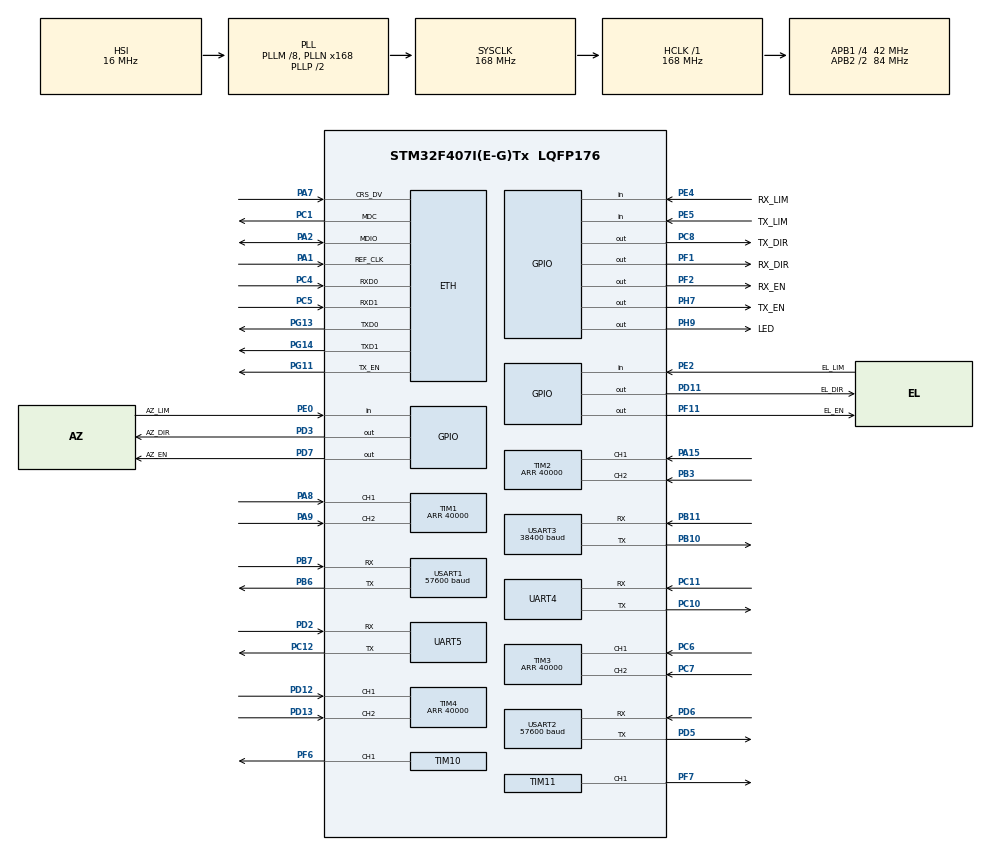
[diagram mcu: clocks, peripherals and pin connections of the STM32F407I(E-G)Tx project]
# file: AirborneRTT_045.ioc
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Dma.Request0=USART1_TX
Dma.Request1=USART2_TX
Dma.Request2=USART3_TX
Dma.Request3=UART4_TX
Dma.UART4_TX.3.Direction=DMA_MEMORY_TO_PERIPH
Dma.UART4_TX.3.FIFOMode=DMA_FIFOMODE_DISABLE
Dma.UART4_TX.3.Instance=DMA1_Stream4
Dma.UART4_TX.3.MemDataAlignment=DMA_MDATAALIGN_BYTE
Dma.UART4_TX.3.MemInc=DMA_MINC_ENABLE
Dma.UART4_TX.3.Mode=DMA_NORMAL
Dma.UART4_TX.3.PeriphDataAlignment=DMA_PDATAALIGN_BYTE
Dma.UART4_TX.3.PeriphInc=DMA_PINC_DISABLE
Dma.UART4_TX.3.Priority=DMA_PRIORITY_LOW
Dma.USART1_TX.0.Direction=DMA_MEMORY_TO_PERIPH
Dma.USART1_TX.0.FIFOMode=DMA_FIFOMODE_DISABLE
Dma.USART1_TX.0.Instance=DMA2_Stream7
Dma.USART1_TX.0.MemDataAlignment=DMA_MDATAALIGN_BYTE
Dma.USART1_TX.0.MemInc=DMA_MINC_ENABLE
Dma.USART1_TX.0.Mode=DMA_NORMAL
Dma.USART1_TX.0.PeriphDataAlignment=DMA_PDATAALIGN_BYTE
Dma.USART1_TX.0.PeriphInc=DMA_PINC_DISABLE
Dma.USART1_TX.0.Priority=DMA_PRIORITY_LOW
Dma.USART2_TX.1.Direction=DMA_MEMORY_TO_PERIPH
Dma.USART2_TX.1.FIFOMode=DMA_FIFOMODE_DISABLE
Dma.USART2_TX.1.Instance=DMA1_Stream6
Dma.USART2_TX.1.MemDataAlignment=DMA_MDATAALIGN_BYTE
Dma.USART2_TX.1.MemInc=DMA_MINC_ENABLE
Dma.USART2_TX.1.Mode=DMA_NORMAL
Dma.USART2_TX.1.PeriphDataAlignment=DMA_PDATAALIGN_BYTE
Dma.USART2_TX.1.PeriphInc=DMA_PINC_DISABLE
Dma.USART2_TX.1.Priority=DMA_PRIORITY_LOW
Dma.USART3_TX.2.Direction=DMA_MEMORY_TO_PERIPH
Dma.USART3_TX.2.FIFOMode=DMA_FIFOMODE_DISABLE
Dma.USART3_TX.2.Instance=DMA1_Stream3
Dma.USART3_TX.2.MemDataAlignment=DMA_MDATAALIGN_BYTE
Dma.USART3_TX.2.MemInc=DMA_MINC_ENABLE
Dma.USART3_TX.2.Mode=DMA_NORMAL
Dma.USART3_TX.2.PeriphDataAlignment=DMA_PDATAALIGN_BYTE
Dma.USART3_TX.2.PeriphInc=DMA_PINC_DISABLE
Dma.USART3_TX.2.Priority=DMA_PRIORITY_LOW
ETH.MediaInterface=ETH_MEDIA_INTERFACE_RMII
ETH.PHY_Name_RMII=userPHY
ETH.PHY_User_Name=LAN_8720A
ETH.PhyAddress=0
LWIP.GATEWAY_ADDRESS=192.168.000.001
LWIP.IP_ADDRESS=192.168.000.101
LWIP.LWIP_DHCP=0
LWIP.LWIP_HTTPD=1
LWIP.NETMASK_ADDRESS=255.255.254.000
LWIP.Version=v2.1.2_Cube
Mcu.Family=STM32F4
Mcu.Name=STM32F407I(E-G)Tx
Mcu.Package=LQFP176
NVIC.DMA1_Stream3_IRQn=true\:0\:0\:false\:false\:true\:false\:false\:true
NVIC.DMA1_Stream4_IRQn=true\:0\:0\:false\:false\:true\:false\:false\:true
NVIC.DMA1_Stream6_IRQn=true\:0\:0\:false\:false\:true\:false\:false\:true
NVIC.DMA2_Stream7_IRQn=true\:0\:0\:false\:false\:true\:false\:false\:true
NVIC.ETH_IRQn=true\:0\:0\:false\:false\:true\:false\:true\:true
NVIC.PriorityGroup=NVIC_PRIORITYGROUP_4
NVIC.TIM1_TRG_COM_TIM11_IRQn=true\:0\:0\:false\:false\:true\:false\:true\:true
NVIC.TIM1_UP_TIM10_IRQn=true\:0\:0\:false\:false\:true\:false\:true\:true
NVIC.TIM5_IRQn=true\:0\:0\:false\:false\:true\:false\:false\:true
NVIC.TimeBase=TIM5_IRQn
NVIC.TimeBaseIP=TIM5
NVIC.UART4_IRQn=true\:0\:0\:false\:false\:true\:false\:true\:true
NVIC.UART5_IRQn=true\:0\:0\:false\:false\:true\:false\:true\:true
NVIC.USART1_IRQn=true\:0\:0\:false\:false\:true\:false\:true\:true
NVIC.USART2_IRQn=true\:0\:0\:false\:false\:true\:false\:true\:true
NVIC.USART3_IRQn=true\:0\:0\:false\:false\:true\:false\:true\:true
PA1.Mode=RMII
PA1.Signal=ETH_REF_CLK
PA15.Signal=S_TIM2_CH1_ETR
PA2.Mode=RMII
PA2.Signal=ETH_MDIO
PA7.Mode=RMII
PA7.Signal=ETH_CRS_DV
PA8.Signal=S_TIM1_CH1
PA9.Signal=S_TIM1_CH2
PB10.Mode=Asynchronous
PB10.Signal=USART3_TX
PB11.Mode=Asynchronous
PB11.Signal=USART3_RX
PB3.Signal=S_TIM2_CH2
PB6.Mode=Asynchronous
PB6.Signal=USART1_TX
PB7.Mode=Asynchronous
PB7.Signal=USART1_RX
PC1.Mode=RMII
PC1.Signal=ETH_MDC
PC10.Mode=Asynchronous
PC10.Signal=UART4_TX
PC11.Mode=Asynchronous
PC11.Signal=UART4_RX
PC12.Mode=Asynchronous
PC12.Signal=UART5_TX
PC4.Mode=RMII
PC4.Signal=ETH_RXD0
PC5.Mode=RMII
PC5.Signal=ETH_RXD1
PC6.Signal=S_TIM3_CH1
PC7.Signal=S_TIM3_CH2
PC8.GPIO_Label=TX_DIR
PC8.Signal=GPIO_Output
PD11.GPIO_Label=EL_DIR
PD11.Signal=GPIO_Output
PD12.Signal=S_TIM4_CH1
PD13.Signal=S_TIM4_CH2
PD2.Mode=Asynchronous
PD2.Signal=UART5_RX
PD3.GPIO_Label=AZ_DIR
PD3.Signal=GPIO_Output
PD5.Mode=Asynchronous
PD5.Signal=USART2_TX
PD6.Mode=Asynchronous
PD6.Signal=USART2_RX
PD7.GPIO_Label=AZ_EN
PD7.Signal=GPIO_Output
PE0.GPIO_Label=AZ_LIM
PE0.Signal=GPIO_Input
PE2.GPIO_Label=EL_LIM
PE2.Signal=GPIO_Input
PE4.GPIO_Label=RX_LIM
PE4.Signal=GPIO_Input
PE5.GPIO_Label=TX_LIM
PE5.Signal=GPIO_Input
PF1.GPIO_Label=RX_DIR
PF1.Signal=GPIO_Output
PF11.GPIO_Label=EL_EN
PF11.Signal=GPIO_Output
PF2.GPIO_Label=RX_EN
PF2.Signal=GPIO_Output
PF6.Signal=S_TIM10_CH1
PF7.Signal=S_TIM11_CH1
PG11.Mode=RMII
PG11.Signal=ETH_TX_EN
PG13.Mode=RMII
PG13.Signal=ETH_TXD0
PG14.Mode=RMII
PG14.Signal=ETH_TXD1
PH0-OSC_IN.Mode=HSE-External-Oscillator
PH0-OSC_IN.Signal=RCC_OSC_IN
PH1-OSC_OUT.Mode=HSE-External-Oscillator
PH1-OSC_OUT.Signal=RCC_OSC_OUT
PH7.GPIO_Label=TX_EN
PH7.Signal=GPIO_Output
PH9.GPIO_Label=LED
PH9.Signal=GPIO_Output
ProjectManager.HeapSize=0x200
ProjectManager.StackSize=0x400
ProjectManager.TargetToolchain=MDK-ARM V5.27
RCC.48MHZClocksFreq_Value=84000000
RCC.AHBFreq_Value=168000000
RCC.APB1CLKDivider=RCC_HCLK_DIV4
RCC.APB1Freq_Value=42000000
RCC.APB1TimFreq_Value=84000000
RCC.APB2CLKDivider=RCC_HCLK_DIV2
RCC.APB2Freq_Value=84000000
RCC.APB2TimFreq_Value=168000000
RCC.CortexFreq_Value=168000000
RCC.HCLKFreq_Value=168000000
RCC.HSE_VALUE=8000000
RCC.HSI_VALUE=16000000
RCC.LSE_VALUE=32768
RCC.PLLM=8
RCC.PLLN=168
RCC.SYSCLKFreq_VALUE=168000000
RCC.SYSCLKSource=RCC_SYSCLKSOURCE_PLLCLK
RCC.VCOOutputFreq_Value=336000000
RealThread.RT-Thread.3.1.3.RTAaThreadCcRTOSJjkernel=true
RealThread.RT-Thread.3.1.3.RT_USING_CONSOLE=0
RealThread.RT-Thread.3.1.3.RT_USING_EVENT=1
RealThread.RT-Thread.3.1.3.RT_USING_MUTEX=1
SH.S_TIM10_CH1.0=TIM10_CH1,PWM Generation1 CH1
SH.S_TIM11_CH1.0=TIM11_CH1,PWM Generation1 CH1
SH.S_TIM1_CH1.0=TIM1_CH1,Encoder_Interface
SH.S_TIM1_CH2.0=TIM1_CH2,Encoder_Interface
SH.S_TIM2_CH1_ETR.0=TIM2_CH1,Encoder_Interface
SH.S_TIM2_CH2.0=TIM2_CH2,Encoder_Interface
SH.S_TIM3_CH1.0=TIM3_CH1,Encoder_Interface
SH.S_TIM3_CH2.0=TIM3_CH2,Encoder_Interface
SH.S_TIM4_CH1.0=TIM4_CH1,Encoder_Interface
SH.S_TIM4_CH2.0=TIM4_CH2,Encoder_Interface
TIM1.AutoReloadPreload=TIM_AUTORELOAD_PRELOAD_ENABLE
TIM1.EncoderMode=TIM_ENCODERMODE_TI12
TIM1.IC1Filter=6
TIM1.IC2Filter=6
TIM1.Period=40000
TIM10.AutoReloadPreload=TIM_AUTORELOAD_PRELOAD_ENABLE
TIM10.Channel=TIM_CHANNEL_1
TIM10.OCFastMode_PWM=TIM_OCFAST_ENABLE
TIM11.AutoReloadPreload=TIM_AUTORELOAD_PRELOAD_ENABLE
TIM11.Channel=TIM_CHANNEL_1
TIM11.OCFastMode_PWM=TIM_OCFAST_ENABLE
TIM2.AutoReloadPreload=TIM_AUTORELOAD_PRELOAD_ENABLE
TIM2.EncoderMode=TIM_ENCODERMODE_TI12
TIM2.IC1Filter=6
TIM2.IC2Filter=6
TIM2.Period=40000
TIM3.AutoReloadPreload=TIM_AUTORELOAD_PRELOAD_ENABLE
TIM3.EncoderMode=TIM_ENCODERMODE_TI12
TIM3.IC1Filter=6
TIM3.IC2Filter=6
TIM3.Period=40000
TIM4.AutoReloadPreload=TIM_AUTORELOAD_PRELOAD_ENABLE
TIM4.EncoderMode=TIM_ENCODERMODE_TI12
TIM4.IC1Filter=6
TIM4.IC2Filter=6
TIM4.Period=40000
UART4.VirtualMode=Asynchronous
UART5.VirtualMode=Asynchronous
USART1.BaudRate=57600
USART1.VirtualMode=VM_ASYNC
USART2.BaudRate=57600
USART2.VirtualMode=VM_ASYNC
USART3.BaudRate=38400
USART3.VirtualMode=VM_ASYNC
VP_LWIP_VS_Enabled.Mode=Enabled
VP_RealThread.RT-Thread_VS_RTOSJjRTAaThread_3.1.3.Mode=RTOSJjRTAaThread
VP_SYS_VS_tim5.Mode=TIM5
VP_TIM10_VS_ClockSourceINT.Mode=Enable_Timer
VP_TIM11_VS_ClockSourceINT.Mode=Enable_Timer
board=custom

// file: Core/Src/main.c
/* USER CODE BEGIN Header */
/**
  ******************************************************************************
  * @file           : main.c
  * @brief          : Main program body
  ******************************************************************************
  * @attention
  *
  * <h2><center>&copy; Copyright (c) 2021 STMicroelectronics.
  * All rights reserved.</center></h2>
  *
  * This software component is licensed by ST under BSD 3-Clause license,
  * the "License"; You may not use this file except in compliance with the
  * License. You may obtain a copy of the License at:
  *                        opensource.org/licenses/BSD-3-Clause
  *
  ******************************************************************************
  */
/* USER CODE END Header */
#include "main.h"
#include "lwip.h"

/* USER CODE BEGIN Includes */
#include "MotorControl.h"
#include "Parameters.h"
#include "Senser.h"
#include "beacon.h"
#include "buc.h"
#include "mems.h"
#include "rtthread.h"
#include "thread_com.h"
#include "thread_ctrl.h"
#include "udp_echoserver.h"
/* USER CODE END Includes */

TIM_HandleTypeDef htim1;
TIM_HandleTypeDef htim2;
TIM_HandleTypeDef htim3;
TIM_HandleTypeDef htim4;
TIM_HandleTypeDef htim10;
TIM_HandleTypeDef htim11;

UART_HandleTypeDef huart4;
UART_HandleTypeDef huart5;
UART_HandleTypeDef huart1;
UART_HandleTypeDef huart2;
UART_HandleTypeDef huart3;
DMA_HandleTypeDef hdma_uart4_tx;
DMA_HandleTypeDef hdma_usart1_tx;
DMA_HandleTypeDef hdma_usart2_tx;
DMA_HandleTypeDef hdma_usart3_tx;

void SystemClock_Config(void);
void MX_GPIO_Init(void);
static void MX_DMA_Init(void);
static void MX_USART1_UART_Init(void);
static void MX_USART2_UART_Init(void);
static void MX_USART3_UART_Init(void);
static void MX_UART4_Init(void);
static void MX_TIM1_Init(void);
static void MX_TIM2_Init(void);
static void MX_TIM3_Init(void);
static void MX_TIM4_Init(void);
static void MX_TIM10_Init(void);
static void MX_TIM11_Init(void);
static void MX_UART5_Init(void);

int main(void)
{
    /* USER CODE BEGIN 1 */
    rt_uint32_t e;
    HAL_GPIO_TogglePin(LED_GPIO_Port, LED_Pin);
    /* USER CODE END 1 */

    /* MCU Configuration--------------------------------------------------------*/

    /* Initialize all configured peripherals */
    MX_GPIO_Init();
    MX_DMA_Init();
    MX_USART1_UART_Init();
    MX_USART2_UART_Init();
    MX_USART3_UART_Init();
    MX_UART4_Init();
    MX_TIM1_Init();
    MX_TIM2_Init();
    MX_TIM3_Init();
    MX_TIM4_Init();
    MX_TIM10_Init();
    MX_TIM11_Init();
    MX_UART5_Init();
    MX_LWIP_Init();
    /* USER CODE BEGIN 2 */
    HAL_GPIO_TogglePin(LED_GPIO_Port, LED_Pin);
    ComInit();
    CtrlInit();
    ParamsInit();
    MotoInit();
    HAL_UART_Receive_IT(&huart1, MEMS_CH, 1);
    HAL_UART_Receive_IT(&huart4, BUC_CH, 1);
    HAL_UART_Receive_IT(&huart5, BC_CH, 1);

    /* USER CODE END 2 */

    /* Infinite loop */
    while (1) {

        /* USER CODE BEGIN 3 */
        if (rt_event_recv(&event_mems, (EVENT_FLAG_MEMSRECV | EVENT_FLAG_TIMEOUT5), RT_EVENT_FLAG_OR | RT_EVENT_FLAG_CLEAR, RT_WAITING_FOREVER, &e) == RT_EOK) {
        }

#ifndef _DEBUG_
        GetMemsData(e);
#else
        while (tickTimer5ms == 0) {
        }
        tickTimer5ms = 0;
        Senser.GPSX = 108.99;
        Senser.GPSY = 34.15;
        Senser.GPSH = 520;
#endif
        PilotLampControl();
        AnalysisDataPC();
        DataCollection();

        if (WorkMode == Mode_Hand_Control) {
        } else {
            //寻零
            if (AZFindZeroEndFlag == 0 || ELFindZeroEndFlag == 0 || ROLLFindZeroEndFlag == 0 || POLFindZeroEndFlag == 0) {
                ZeroCheck();
            } else {
                //初始航向校准
                if (HeadCheckFlag == 0) {
                    WorkMode = Mode_HeadCheck;
                    HeadCalibrate();
                }

                switch (WorkMode) {
                case Mode_Stand_By:
                    StandBy();
                    break;
                case Mode_AimSatellite:
                    AimSatellite();
                    break;
                case Mode_Tracking:
                    AGCFilter();
                    TrackCircle();
                    MotoCtr.AZSpeed = PositionControlAZ(MotoCtr.AZPerset, Senser.Angle_AZ);
                    MotoCtr.ESpeed = PositionControlEL(MotoCtr.ELPerset, Senser.Angle_EL);
                    MotoCtr.ROLLSpeed = PositionControlROLL(MotoCtr.ROLLPerset, Senser.Angle_ROLL);
                    MotoCtr.POLSpeed = PositionControlPOLPoint(MotoCtr.POLPerset, Senser.Angle_POL);
                    break;
                case Mode_Searching:
                    SearchAGCMax(Senser.AgcMAx.AZg, Senser.AgcMAx.ELg);
                    break;
                case Mode_Debug_Speed:
                    break;
                case Mode_Debug_Position:
                    DebugPosition();
                    break;
                case Mode_Debug_Position_Sin:
                    DebugPositionSin();
                    break;
                default:
                    break;
                }
            }
        }

        // MotoCtr.AZSpeed = 0;
        // MotoCtr.ESpeed = 0;
        // MotoCtr.ROLLSpeed = 0;
        // MotoCtr.POLSpeed = 0;

        SpeedCtrl();

        BugSys();

        //设置接收机参数，载波频率、符码率
        if (BC_IsNeedSet() != STATE_OK) {
            BC_SetBCInfo();
            BC_GetBCInfo();
        }

        // MEMS航向校准
        AmandMemsNew();

        //若需要进行数据存储，则将数据写入Flash
        FlashDataWrite();

        //App_process();
    }
    /* USER CODE END 3 */
}

void SystemClock_Config(void)
{
    RCC_OscInitTypeDef RCC_OscInitStruct = { 0 };
    RCC_ClkInitTypeDef RCC_ClkInitStruct = { 0 };

    /** Configure the main internal regulator output voltage
  */
    __HAL_RCC_PWR_CLK_ENABLE();
    __HAL_PWR_VOLTAGESCALING_CONFIG(PWR_REGULATOR_VOLTAGE_SCALE1);
    /** Initializes the RCC Oscillators according to the specified parameters
  * in the RCC_OscInitTypeDef structure.
  */
    RCC_OscInitStruct.OscillatorType = RCC_OSCILLATORTYPE_HSI;
    RCC_OscInitStruct.HSIState = RCC_HSI_ON;
    RCC_OscInitStruct.HSICalibrationValue = RCC_HSICALIBRATION_DEFAULT;
    RCC_OscInitStruct.PLL.PLLState = RCC_PLL_ON;
    RCC_OscInitStruct.PLL.PLLSource = RCC_PLLSOURCE_HSI;
    RCC_OscInitStruct.PLL.PLLM = 8;
    RCC_OscInitStruct.PLL.PLLN = 168;
    RCC_OscInitStruct.PLL.PLLP = RCC_PLLP_DIV2;
    RCC_OscInitStruct.PLL.PLLQ = 4;
    if (HAL_RCC_OscConfig(&RCC_OscInitStruct) != HAL_OK) {
        Error_Handler();
    }
    /** Initializes the CPU, AHB and APB buses clocks
  */
    RCC_ClkInitStruct.ClockType = RCC_CLOCKTYPE_HCLK | RCC_CLOCKTYPE_SYSCLK
        | RCC_CLOCKTYPE_PCLK1 | RCC_CLOCKTYPE_PCLK2;
    RCC_ClkInitStruct.SYSCLKSource = RCC_SYSCLKSOURCE_PLLCLK;
    RCC_ClkInitStruct.AHBCLKDivider = RCC_SYSCLK_DIV1;
    RCC_ClkInitStruct.APB1CLKDivider = RCC_HCLK_DIV4;
    RCC_ClkInitStruct.APB2CLKDivider = RCC_HCLK_DIV2;

    if (HAL_RCC_ClockConfig(&RCC_ClkInitStruct, FLASH_LATENCY_5) != HAL_OK) {
        Error_Handler();
    }
}

static void MX_TIM1_Init(void)
{

    TIM_Encoder_InitTypeDef sConfig = { 0 };
    TIM_MasterConfigTypeDef sMasterConfig = { 0 };

    htim1.Instance = TIM1;
    htim1.Init.Prescaler = 0;
    htim1.Init.CounterMode = TIM_COUNTERMODE_UP;
    htim1.Init.Period = 40000;
    htim1.Init.ClockDivision = TIM_CLOCKDIVISION_DIV1;
    htim1.Init.RepetitionCounter = 0;
    htim1.Init.AutoReloadPreload = TIM_AUTORELOAD_PRELOAD_ENABLE;
    sConfig.EncoderMode = TIM_ENCODERMODE_TI12;
    sConfig.IC1Polarity = TIM_ICPOLARITY_RISING;
    sConfig.IC1Selection = TIM_ICSELECTION_DIRECTTI;
    sConfig.IC1Prescaler = TIM_ICPSC_DIV1;
    sConfig.IC1Filter = 6;
    sConfig.IC2Polarity = TIM_ICPOLARITY_RISING;
    sConfig.IC2Selection = TIM_ICSELECTION_DIRECTTI;
    sConfig.IC2Prescaler = TIM_ICPSC_DIV1;
    sConfig.IC2Filter = 6;
    if (HAL_TIM_Encoder_Init(&htim1, &sConfig) != HAL_OK) {
        Error_Handler();
    }
    sMasterConfig.MasterOutputTrigger = TIM_TRGO_RESET;
    sMasterConfig.MasterSlaveMode = TIM_MASTERSLAVEMODE_DISABLE;
    if (HAL_TIMEx_MasterConfigSynchronization(&htim1, &sMasterConfig) != HAL_OK) {
        Error_Handler();
    }
    /* USER CODE BEGIN TIM1_Init 2 */
    HAL_TIM_Base_Start_IT(&htim1);
    /* USER CODE END TIM1_Init 2 */
}

static void MX_TIM2_Init(void)
{

    TIM_Encoder_InitTypeDef sConfig = { 0 };
    TIM_MasterConfigTypeDef sMasterConfig = { 0 };

    htim2.Instance = TIM2;
    htim2.Init.Prescaler = 0;
    htim2.Init.CounterMode = TIM_COUNTERMODE_UP;
    htim2.Init.Period = 40000;
    htim2.Init.ClockDivision = TIM_CLOCKDIVISION_DIV1;
    htim2.Init.AutoReloadPreload = TIM_AUTORELOAD_PRELOAD_ENABLE;
    sConfig.EncoderMode = TIM_ENCODERMODE_TI12;
    sConfig.IC1Polarity = TIM_ICPOLARITY_RISING;
    sConfig.IC1Selection = TIM_ICSELECTION_DIRECTTI;
    sConfig.IC1Prescaler = TIM_ICPSC_DIV1;
    sConfig.IC1Filter = 6;
    sConfig.IC2Polarity = TIM_ICPOLARITY_RISING;
    sConfig.IC2Selection = TIM_ICSELECTION_DIRECTTI;
    sConfig.IC2Prescaler = TIM_ICPSC_DIV1;
    sConfig.IC2Filter = 6;
    if (HAL_TIM_Encoder_Init(&htim2, &sConfig) != HAL_OK) {
        Error_Handler();
    }
    sMasterConfig.MasterOutputTrigger = TIM_TRGO_RESET;
    sMasterConfig.MasterSlaveMode = TIM_MASTERSLAVEMODE_DISABLE;
    if (HAL_TIMEx_MasterConfigSynchronization(&htim2, &sMasterConfig) != HAL_OK) {
        Error_Handler();
    }
    /* USER CODE BEGIN TIM2_Init 2 */
    HAL_TIM_Base_Start_IT(&htim2);
    /* USER CODE END TIM2_Init 2 */
}

static void MX_TIM3_Init(void)
{

    TIM_Encoder_InitTypeDef sConfig = { 0 };
    TIM_MasterConfigTypeDef sMasterConfig = { 0 };

    htim3.Instance = TIM3;
    htim3.Init.Prescaler = 0;
    htim3.Init.CounterMode = TIM_COUNTERMODE_UP;
    htim3.Init.Period = 40000;
    htim3.Init.ClockDivision = TIM_CLOCKDIVISION_DIV1;
    htim3.Init.AutoReloadPreload = TIM_AUTORELOAD_PRELOAD_ENABLE;
    sConfig.EncoderMode = TIM_ENCODERMODE_TI12;
    sConfig.IC1Polarity = TIM_ICPOLARITY_RISING;
    sConfig.IC1Selection = TIM_ICSELECTION_DIRECTTI;
    sConfig.IC1Prescaler = TIM_ICPSC_DIV1;
    sConfig.IC1Filter = 6;
    sConfig.IC2Polarity = TIM_ICPOLARITY_RISING;
    sConfig.IC2Selection = TIM_ICSELECTION_DIRECTTI;
    sConfig.IC2Prescaler = TIM_ICPSC_DIV1;
    sConfig.IC2Filter = 6;
    if (HAL_TIM_Encoder_Init(&htim3, &sConfig) != HAL_OK) {
        Error_Handler();
    }
    sMasterConfig.MasterOutputTrigger = TIM_TRGO_RESET;
    sMasterConfig.MasterSlaveMode = TIM_MASTERSLAVEMODE_DISABLE;
    if (HAL_TIMEx_MasterConfigSynchronization(&htim3, &sMasterConfig) != HAL_OK) {
        Error_Handler();
    }
    /* USER CODE BEGIN TIM3_Init 2 */
    HAL_TIM_Base_Start_IT(&htim3);
    /* USER CODE END TIM3_Init 2 */
}

static void MX_TIM4_Init(void)
{

    TIM_Encoder_InitTypeDef sConfig = { 0 };
    TIM_MasterConfigTypeDef sMasterConfig = { 0 };

    htim4.Instance = TIM4;
    htim4.Init.Prescaler = 0;
    htim4.Init.CounterMode = TIM_COUNTERMODE_UP;
    htim4.Init.Period = 40000;
    htim4.Init.ClockDivision = TIM_CLOCKDIVISION_DIV1;
    htim4.Init.AutoReloadPreload = TIM_AUTORELOAD_PRELOAD_ENABLE;
    sConfig.EncoderMode = TIM_ENCODERMODE_TI12;
    sConfig.IC1Polarity = TIM_ICPOLARITY_RISING;
    sConfig.IC1Selection = TIM_ICSELECTION_DIRECTTI;
    sConfig.IC1Prescaler = TIM_ICPSC_DIV1;
    sConfig.IC1Filter = 6;
    sConfig.IC2Polarity = TIM_ICPOLARITY_RISING;
    sConfig.IC2Selection = TIM_ICSELECTION_DIRECTTI;
    sConfig.IC2Prescaler = TIM_ICPSC_DIV1;
    sConfig.IC2Filter = 6;
    if (HAL_TIM_Encoder_Init(&htim4, &sConfig) != HAL_OK) {
        Error_Handler();
    }
    sMasterConfig.MasterOutputTrigger = TIM_TRGO_RESET;
    sMasterConfig.MasterSlaveMode = TIM_MASTERSLAVEMODE_DISABLE;
    if (HAL_TIMEx_MasterConfigSynchronization(&htim4, &sMasterConfig) != HAL_OK) {
        Error_Handler();
    }
    /* USER CODE BEGIN TIM4_Init 2 */
    HAL_TIM_Base_Start_IT(&htim4);
    /* USER CODE END TIM4_Init 2 */
}

static void MX_TIM10_Init(void)
{

    TIM_OC_InitTypeDef sConfigOC = { 0 };

    htim10.Instance = TIM10;
    htim10.Init.Prescaler = 0;
    htim10.Init.CounterMode = TIM_COUNTERMODE_UP;
    htim10.Init.Period = 65535;
    htim10.Init.ClockDivision = TIM_CLOCKDIVISION_DIV1;
    htim10.Init.AutoReloadPreload = TIM_AUTORELOAD_PRELOAD_ENABLE;
    if (HAL_TIM_Base_Init(&htim10) != HAL_OK) {
        Error_Handler();
    }
    if (HAL_TIM_PWM_Init(&htim10) != HAL_OK) {
        Error_Handler();
    }
    sConfigOC.OCMode = TIM_OCMODE_PWM1;
    sConfigOC.Pulse = 0;
    sConfigOC.OCPolarity = TIM_OCPOLARITY_HIGH;
    sConfigOC.OCFastMode = TIM_OCFAST_ENABLE;
    if (HAL_TIM_PWM_ConfigChannel(&htim10, &sConfigOC, TIM_CHANNEL_1) != HAL_OK) {
        Error_Handler();
    }
    /* USER CODE BEGIN TIM10_Init 2 */
    HAL_TIM_PWM_Start(&htim10, TIM_CHANNEL_1);
    /* USER CODE END TIM10_Init 2 */
    HAL_TIM_MspPostInit(&htim10);
}

static void MX_TIM11_Init(void)
{

    TIM_OC_InitTypeDef sConfigOC = { 0 };

    htim11.Instance = TIM11;
    htim11.Init.Prescaler = 0;
    htim11.Init.CounterMode = TIM_COUNTERMODE_UP;
    htim11.Init.Period = 65535;
    htim11.Init.ClockDivision = TIM_CLOCKDIVISION_DIV1;
    htim11.Init.AutoReloadPreload = TIM_AUTORELOAD_PRELOAD_ENABLE;
    if (HAL_TIM_Base_Init(&htim11) != HAL_OK) {
        Error_Handler();
    }
    if (HAL_TIM_PWM_Init(&htim11) != HAL_OK) {
        Error_Handler();
    }
    sConfigOC.OCMode = TIM_OCMODE_PWM1;
    sConfigOC.Pulse = 0;
    sConfigOC.OCPolarity = TIM_OCPOLARITY_HIGH;
    sConfigOC.OCFastMode = TIM_OCFAST_ENABLE;
    if (HAL_TIM_PWM_ConfigChannel(&htim11, &sConfigOC, TIM_CHANNEL_1) != HAL_OK) {
        Error_Handler();
    }
    /* USER CODE BEGIN TIM11_Init 2 */
    HAL_TIM_PWM_Start(&htim11, TIM_CHANNEL_1);

    /* USER CODE END TIM11_Init 2 */
    HAL_TIM_MspPostInit(&htim11);
}

static void MX_UART4_Init(void)
{

    huart4.Instance = UART4;
    huart4.Init.BaudRate = 115200;
    huart4.Init.WordLength = UART_WORDLENGTH_8B;
    huart4.Init.StopBits = UART_STOPBITS_1;
    huart4.Init.Parity = UART_PARITY_NONE;
    huart4.Init.Mode = UART_MODE_TX_RX;
    huart4.Init.HwFlowCtl = UART_HWCONTROL_NONE;
    huart4.Init.OverSampling = UART_OVERSAMPLING_16;
    if (HAL_UART_Init(&huart4) != HAL_OK) {
        Error_Handler();
    }
}

static void MX_UART5_Init(void)
{

    huart5.Instance = UART5;
    huart5.Init.BaudRate = 115200;
    huart5.Init.WordLength = UART_WORDLENGTH_8B;
    huart5.Init.StopBits = UART_STOPBITS_1;
    huart5.Init.Parity = UART_PARITY_NONE;
    huart5.Init.Mode = UART_MODE_TX_RX;
    huart5.Init.HwFlowCtl = UART_HWCONTROL_NONE;
    huart5.Init.OverSampling = UART_OVERSAMPLING_16;
    if (HAL_UART_Init(&huart5) != HAL_OK) {
        Error_Handler();
    }
}

static void MX_USART1_UART_Init(void)
{

    huart1.Instance = USART1;
    huart1.Init.BaudRate = 57600;
    huart1.Init.WordLength = UART_WORDLENGTH_8B;
    huart1.Init.StopBits = UART_STOPBITS_1;
    huart1.Init.Parity = UART_PARITY_NONE;
    huart1.Init.Mode = UART_MODE_TX_RX;
    huart1.Init.HwFlowCtl = UART_HWCONTROL_NONE;
    huart1.Init.OverSampling = UART_OVERSAMPLING_16;
    if (HAL_UART_Init(&huart1) != HAL_OK) {
        Error_Handler();
    }
}

static void MX_USART2_UART_Init(void)
{

    huart2.Instance = USART2;
    huart2.Init.BaudRate = 57600;
    huart2.Init.WordLength = UART_WORDLENGTH_8B;
    huart2.Init.StopBits = UART_STOPBITS_1;
    huart2.Init.Parity = UART_PARITY_NONE;
    huart2.Init.Mode = UART_MODE_TX_RX;
    huart2.Init.HwFlowCtl = UART_HWCONTROL_NONE;
    huart2.Init.OverSampling = UART_OVERSAMPLING_16;
    if (HAL_UART_Init(&huart2) != HAL_OK) {
        Error_Handler();
    }
}

static void MX_USART3_UART_Init(void)
{

    huart3.Instance = USART3;
    huart3.Init.BaudRate = 38400;
    huart3.Init.WordLength = UART_WORDLENGTH_8B;
    huart3.Init.StopBits = UART_STOPBITS_1;
    huart3.Init.Parity = UART_PARITY_NONE;
    huart3.Init.Mode = UART_MODE_TX_RX;
    huart3.Init.HwFlowCtl = UART_HWCONTROL_NONE;
    huart3.Init.OverSampling = UART_OVERSAMPLING_16;
    if (HAL_UART_Init(&huart3) != HAL_OK) {
        Error_Handler();
    }
}

static void MX_DMA_Init(void)
{

    /* DMA controller clock enable */
    __HAL_RCC_DMA2_CLK_ENABLE();
    __HAL_RCC_DMA1_CLK_ENABLE();

    /* DMA interrupt init */
    /* DMA1_Stream3_IRQn interrupt configuration */
    HAL_NVIC_SetPriority(DMA1_Stream3_IRQn, 0, 0);
    HAL_NVIC_EnableIRQ(DMA1_Stream3_IRQn);
    /* DMA1_Stream4_IRQn interrupt configuration */
    HAL_NVIC_SetPriority(DMA1_Stream4_IRQn, 0, 0);
    HAL_NVIC_EnableIRQ(DMA1_Stream4_IRQn);
    /* DMA1_Stream6_IRQn interrupt configuration */
    HAL_NVIC_SetPriority(DMA1_Stream6_IRQn, 0, 0);
    HAL_NVIC_EnableIRQ(DMA1_Stream6_IRQn);
    /* DMA2_Stream7_IRQn interrupt configuration */
    HAL_NVIC_SetPriority(DMA2_Stream7_IRQn, 0, 0);
    HAL_NVIC_EnableIRQ(DMA2_Stream7_IRQn);
}

void MX_GPIO_Init(void)
{
    GPIO_InitTypeDef GPIO_InitStruct = { 0 };

    /* GPIO Ports Clock Enable */
    __HAL_RCC_GPIOE_CLK_ENABLE();
    __HAL_RCC_GPIOF_CLK_ENABLE();
    __HAL_RCC_GPIOH_CLK_ENABLE();
    __HAL_RCC_GPIOC_CLK_ENABLE();
    __HAL_RCC_GPIOA_CLK_ENABLE();
    __HAL_RCC_GPIOB_CLK_ENABLE();
    __HAL_RCC_GPIOD_CLK_ENABLE();
    __HAL_RCC_GPIOG_CLK_ENABLE();

    /*Configure GPIO pin Output Level */
    HAL_GPIO_WritePin(GPIOF, RX_DIR_Pin | RX_EN_Pin | EL_EN_Pin, GPIO_PIN_RESET);

    /*Configure GPIO pin Output Level */
    HAL_GPIO_WritePin(GPIOH, TX_EN_Pin | LED_Pin, GPIO_PIN_RESET);

    /*Configure GPIO pin Output Level */
    HAL_GPIO_WritePin(GPIOD, EL_DIR_Pin | AZ_DIR_Pin | AZ_EN_Pin, GPIO_PIN_RESET);

    /*Configure GPIO pin Output Level */
    HAL_GPIO_WritePin(TX_DIR_GPIO_Port, TX_DIR_Pin, GPIO_PIN_RESET);

    /*Configure GPIO pin Output Level */
    HAL_GPIO_WritePin(ETH_RST_GPIO_Port, ETH_RST_Pin, GPIO_PIN_RESET);

    /*Configure GPIO pins : EL_LIM_Pin RX_LIM_Pin TX_LIM_Pin AZ_LIM_Pin */
    GPIO_InitStruct.Pin = EL_LIM_Pin | RX_LIM_Pin | TX_LIM_Pin | AZ_LIM_Pin;
    GPIO_InitStruct.Mode = GPIO_MODE_INPUT;
    GPIO_InitStruct.Pull = GPIO_NOPULL;
    HAL_GPIO_Init(GPIOE, &GPIO_InitStruct);

    /*Configure GPIO pins : RX_DIR_Pin RX_EN_Pin EL_EN_Pin */
    GPIO_InitStruct.Pin = RX_DIR_Pin | RX_EN_Pin | EL_EN_Pin;
    GPIO_InitStruct.Mode = GPIO_MODE_OUTPUT_PP;
    GPIO_InitStruct.Pull = GPIO_NOPULL;
    GPIO_InitStruct.Speed = GPIO_SPEED_FREQ_LOW;
    HAL_GPIO_Init(GPIOF, &GPIO_InitStruct);

    /*Configure GPIO pins : TX_EN_Pin LED_Pin */
    GPIO_InitStruct.Pin = TX_EN_Pin | LED_Pin;
    GPIO_InitStruct.Mode = GPIO_MODE_OUTPUT_PP;
    GPIO_InitStruct.Pull = GPIO_NOPULL;
    GPIO_InitStruct.Speed = GPIO_SPEED_FREQ_LOW;
    HAL_GPIO_Init(GPIOH, &GPIO_InitStruct);

    /*Configure GPIO pins : EL_DIR_Pin AZ_DIR_Pin AZ_EN_Pin */
    GPIO_InitStruct.Pin = EL_DIR_Pin | AZ_DIR_Pin | AZ_EN_Pin;
    GPIO_InitStruct.Mode = GPIO_MODE_OUTPUT_PP;
    GPIO_InitStruct.Pull = GPIO_NOPULL;
    GPIO_InitStruct.Speed = GPIO_SPEED_FREQ_LOW;
    HAL_GPIO_Init(GPIOD, &GPIO_InitStruct);

    /*Configure GPIO pin : TX_DIR_Pin */
    GPIO_InitStruct.Pin = TX_DIR_Pin;
    GPIO_InitStruct.Mode = GPIO_MODE_OUTPUT_PP;
    GPIO_InitStruct.Pull = GPIO_NOPULL;
    GPIO_InitStruct.Speed = GPIO_SPEED_FREQ_LOW;
    HAL_GPIO_Init(TX_DIR_GPIO_Port, &GPIO_InitStruct);

    /*Configure GPIO pin : ETH_RST_Pin */
    GPIO_InitStruct.Pin = ETH_RST_Pin;
    GPIO_InitStruct.Mode = GPIO_MODE_OUTPUT_PP;
    GPIO_InitStruct.Pull = GPIO_NOPULL;
    GPIO_InitStruct.Speed = GPIO_SPEED_FREQ_LOW;
    HAL_GPIO_Init(ETH_RST_GPIO_Port, &GPIO_InitStruct);
}

/* USER CODE BEGIN 4 */

void HAL_UART_RxCpltCallback(UART_HandleTypeDef* huart)
{
    UNUSED(huart);
    if (huart == &huart1) {
        MEMS_UART_RecvIT(huart);
    } else if (huart == &huart2) {
    } else if (huart == &huart3) {
        BUC_UART_RecvIT(huart);
    } else if (huart == &huart4) {
        BC_UART_RecvIT(huart);
    } else if (huart == &huart5) {
        MEMS_UART_RecvIT(huart);
    }
}
/* USER CODE END 4 */

void HAL_TIM_PeriodElapsedCallback(TIM_HandleTypeDef* htim)
{
    /* USER CODE BEGIN Callback 0 */
    uint16_t temp = 0;
    temp = htim->Instance->CR1;
    temp = (temp >> 4) & 0x01;
    if (htim->Instance == TIM1) {
        if (temp == 0x0001) {
            Senser.AZEncoder.PeriodCount++;
        } else if (temp == 0x0000) {
            Senser.AZEncoder.PeriodCount--;
        }
    } else if (htim->Instance == TIM2) {
        if (temp == 0x0001) {
            Senser.ELEncoder.PeriodCount--;
        } else if (temp == 0x0000) {
            Senser.ELEncoder.PeriodCount++;
        }
    } else if (htim->Instance == TIM3) {
        if (temp == 0x0001) {
            Senser.ROLLEncoder.PeriodCount--;
        } else if (temp == 0x0000) {
            Senser.ROLLEncoder.PeriodCount++;
        }
    } else if (htim->Instance == TIM4) {
        if (temp == 0x0001) {
            Senser.POLEncoder.PeriodCount--;
        } else if (temp == 0x0000) {
            Senser.POLEncoder.PeriodCount++;
        }
    }

    /* USER CODE END Callback 0 */
    if (htim->Instance == TIM5) {
        HAL_IncTick();
    }
}

void Error_Handler(void)
{
    __disable_irq();
    while (1) {
    }
}

/************************ (C) COPYRIGHT STMicroelectronics *****END OF FILE****/
